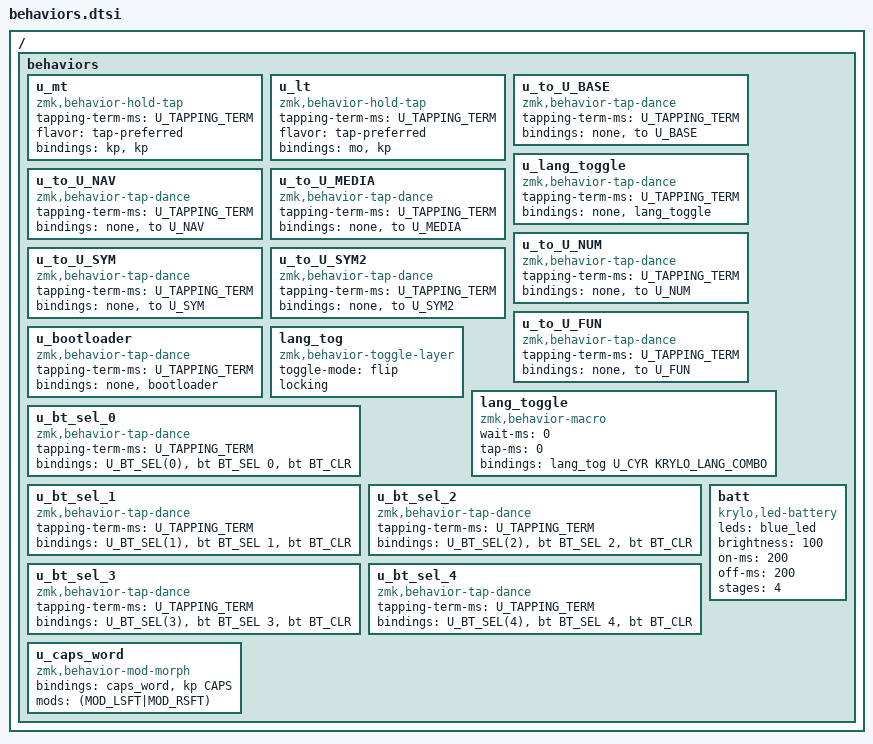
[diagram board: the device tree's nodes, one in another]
// Requires the ZMK system includes: behaviors.dtsi, dt-bindings

#include "macros.h"

/ {
    behaviors {
        // Hold-tap: hold = modifier, tap = key (miryoku U_MT).
        u_mt: u_mt {
            compatible = "zmk,behavior-hold-tap";
            #binding-cells = <2>;
            tapping-term-ms = <U_TAPPING_TERM>;
            flavor = "tap-preferred";
            bindings = <&kp>, <&kp>;
        };
        // Hold-tap: hold = momentary layer, tap = key (miryoku U_LT).
        u_lt: u_lt {
            compatible = "zmk,behavior-hold-tap";
            #binding-cells = <2>;
            tapping-term-ms = <U_TAPPING_TERM>;
            flavor = "tap-preferred";
            bindings = <&mo>, <&kp>;
        };

        // Double-tap layer guards (miryoku u_to_U_*). Double-tap to switch
        // to the layer, single tap does nothing.
        u_to_U_BASE: u_to_U_BASE {
            compatible = "zmk,behavior-tap-dance";
            #binding-cells = <0>;
            tapping-term-ms = <U_TAPPING_TERM>;
            bindings = <&none>, <&to U_BASE>;
        };
        u_lang_toggle: u_lang_toggle {
            compatible = "zmk,behavior-tap-dance";
            #binding-cells = <0>;
            tapping-term-ms = <U_TAPPING_TERM>;
            bindings = <&none>, <&lang_toggle>;
        };
        u_to_U_NAV: u_to_U_NAV {
            compatible = "zmk,behavior-tap-dance";
            #binding-cells = <0>;
            tapping-term-ms = <U_TAPPING_TERM>;
            bindings = <&none>, <&to U_NAV>;
        };
        u_to_U_MEDIA: u_to_U_MEDIA {
            compatible = "zmk,behavior-tap-dance";
            #binding-cells = <0>;
            tapping-term-ms = <U_TAPPING_TERM>;
            bindings = <&none>, <&to U_MEDIA>;
        };
        u_to_U_NUM: u_to_U_NUM {
            compatible = "zmk,behavior-tap-dance";
            #binding-cells = <0>;
            tapping-term-ms = <U_TAPPING_TERM>;
            bindings = <&none>, <&to U_NUM>;
        };
        u_to_U_SYM: u_to_U_SYM {
            compatible = "zmk,behavior-tap-dance";
            #binding-cells = <0>;
            tapping-term-ms = <U_TAPPING_TERM>;
            bindings = <&none>, <&to U_SYM>;
        };
        u_to_U_SYM2: u_to_U_SYM2 {
            compatible = "zmk,behavior-tap-dance";
            #binding-cells = <0>;
            tapping-term-ms = <U_TAPPING_TERM>;
            bindings = <&none>, <&to U_SYM2>;
        };
        u_to_U_FUN: u_to_U_FUN {
            compatible = "zmk,behavior-tap-dance";
            #binding-cells = <0>;
            tapping-term-ms = <U_TAPPING_TERM>;
            bindings = <&none>, <&to U_FUN>;
        };

        // Double-tap bootloader guard
        u_bootloader: u_bootloader {
            compatible = "zmk,behavior-tap-dance";
            #binding-cells = <0>;
            tapping-term-ms = <U_TAPPING_TERM>;
            bindings = <&none>, <&bootloader>;
        };

        // Language toggle
        lang_tog: lang_tog {
            compatible = "zmk,behavior-toggle-layer";
            #binding-cells = <1>;
            toggle-mode = "flip";
            locking; // Locking keeps it active across transient &to / &mo layer transitions.
        };
        // Single key that flip
        lang_toggle: lang_toggle {
            compatible = "zmk,behavior-macro";
            #binding-cells = <0>;
            wait-ms = <0>;
            tap-ms = <0>;
            bindings = <&lang_tog U_CYR KRYLO_LANG_COMBO>;
        };

        // Bluetooth profile select; double-tap to also clear the profile.
        u_bt_sel_0: u_bt_sel_0 {
            compatible = "zmk,behavior-tap-dance";
            #binding-cells = <0>;
            tapping-term-ms = <U_TAPPING_TERM>;
            bindings = <U_BT_SEL(0)>, <&bt BT_SEL 0 &bt BT_CLR>;
        };
        u_bt_sel_1: u_bt_sel_1 {
            compatible = "zmk,behavior-tap-dance";
            #binding-cells = <0>;
            tapping-term-ms = <U_TAPPING_TERM>;
            bindings = <U_BT_SEL(1)>, <&bt BT_SEL 1 &bt BT_CLR>;
        };
        u_bt_sel_2: u_bt_sel_2 {
            compatible = "zmk,behavior-tap-dance";
            #binding-cells = <0>;
            tapping-term-ms = <U_TAPPING_TERM>;
            bindings = <U_BT_SEL(2)>, <&bt BT_SEL 2 &bt BT_CLR>;
        };
        u_bt_sel_3: u_bt_sel_3 {
            compatible = "zmk,behavior-tap-dance";
            #binding-cells = <0>;
            tapping-term-ms = <U_TAPPING_TERM>;
            bindings = <U_BT_SEL(3)>, <&bt BT_SEL 3 &bt BT_CLR>;
        };
        u_bt_sel_4: u_bt_sel_4 {
            compatible = "zmk,behavior-tap-dance";
            #binding-cells = <0>;
            tapping-term-ms = <U_TAPPING_TERM>;
            bindings = <U_BT_SEL(4)>, <&bt BT_SEL 4 &bt BT_CLR>;
        };

        // Caps word; hold Shift for regular Caps Lock.
        u_caps_word: u_caps_word {
            compatible = "zmk,behavior-mod-morph";
            #binding-cells = <0>;
            bindings = <&caps_word>, <&kp CAPS>;
            mods = <(MOD_LSFT|MOD_RSFT)>;
        };

        batt: batt {
            compatible = "krylo,led-battery";
            #binding-cells = <0>;
            leds = <&blue_led>;
            brightness = <100>;
            on-ms = <200>;
            off-ms = <200>;
            stages = <4>;
        };
    };
};
